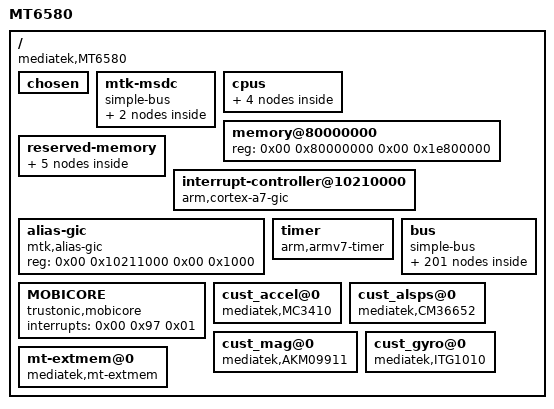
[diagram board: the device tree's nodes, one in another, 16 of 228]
/dts-v1/;

/ {
	model = "MT6580";
	compatible = "mediatek,MT6580";
	interrupt-parent = <0x01>;
	#address-cells = <0x02>;
	#size-cells = <0x02>;

	chosen {
		bootargs = "console=tty0 console=ttyMT0,921600n1 root=/dev/ram initrd=0x84000000,0x400000 loglevel=8";
		atag,videolfb-fb_base = <0x9e800000>;
		atag,videolfb-islcmfound = <0x01>;
		atag,videolfb-fps = <0x1770>;
		atag,videolfb-vramSize = <0x1800000>;
		atag,videolfb-lcmname = "nt35590_AUO";
	};

	mtk-msdc {
		compatible = "simple-bus";
		#address-cells = <0x01>;
		#size-cells = <0x01>;
		ranges = <0x00 0x00 0x00 0xffffffff>;

		MSDC0@0x11120000 {
			compatible = "mediatek,MSDC0";
			reg = <0x11120000 0x10000 0x10001e84 0x02>;
			interrupts = <0x00 0x26 0x08>;
		};

		MSDC1@0x11130000 {
			compatible = "mediatek,MSDC1";
			reg = <0x11130000 0x10000 0x10001e84 0x02>;
			interrupts = <0x00 0x27 0x08>;
		};
	};

	cpus {
		#address-cells = <0x01>;
		#size-cells = <0x00>;

		cpu@0 {
			device_type = "cpu";
			compatible = "arm,cortex-a7";
			reg = <0x00>;
			clock-frequency = <0x6553f100>;
		};

		cpu@1 {
			device_type = "cpu";
			compatible = "arm,cortex-a7";
			reg = <0x01>;
			clock-frequency = <0x6553f100>;
		};

		cpu@2 {
			device_type = "cpu";
			compatible = "arm,cortex-a7";
			reg = <0x02>;
			clock-frequency = <0x6553f100>;
		};

		cpu@3 {
			device_type = "cpu";
			compatible = "arm,cortex-a7";
			reg = <0x03>;
			clock-frequency = <0x6553f100>;
		};
	};

	memory@80000000 {
		device_type = "memory";
		reg = <0x00 0x80000000 0x00 0x1e800000>;
	};

	reserved-memory {
		#address-cells = <0x02>;
		#size-cells = <0x02>;
		ranges;

		reserve-memory-ccci_md1 {
			compatible = "reserve-memory-ccci_md1";
			no-map;
			size = <0x00 0x1800000>;
			alignment = <0x00 0x2000000>;
			alloc-ranges = <0x00 0x80000000 0x00 0x80000000>;
		};

		pstore-reserved-memory {
			compatible = "pstore-reserve-memory";
			reg = <0x00 0x83f10000 0x00 0xe0000>;
		};

		mrdump-reserved-memory {
			compatible = "mrdump-reserved-memory";
			reg = <0x00 0x81f00000 0x00 0x2000>;
		};

		preloader-reserved-memory {
			compatible = "mrdump-reserved-memory";
			reg = <0x00 0x82000000 0x00 0x200000>;
		};

		lk-reserved-memory {
			compatible = "mrdump-reserved-memory";
			reg = <0x00 0x81e00000 0x00 0x100000>;
		};
	};

	interrupt-controller@10210000 {
		compatible = "arm,cortex-a7-gic";
		#interrupt-cells = <0x03>;
		#address-cells = <0x00>;
		interrupt-controller;
		reg = <0x00 0x10211000 0x00 0x1000 0x00 0x10212000 0x00 0x1000 0x00 0x10200100 0x00 0x1000>;
		interrupts = <0x01 0x09 0xf04>;
		linux,phandle = <0x01>;
		phandle = <0x01>;
	};

	alias-gic {
		compatible = "mtk,alias-gic";
		reg = <0x00 0x10211000 0x00 0x1000>;
	};

	timer {
		compatible = "arm,armv7-timer";
		interrupts = <0x01 0x0d 0x08 0x01 0x0e 0x08 0x01 0x0b 0x08 0x01 0x0a 0x08>;
		clock-frequency = <0xc65d40>;
	};

	bus {
		compatible = "simple-bus";
		#address-cells = <0x01>;
		#size-cells = <0x01>;
		ranges = <0x00 0x00 0x00 0xffffffff>;

		TOPCKGEN@0x10000000 {
			compatible = "mediatek,TOPCKGEN";
			reg = <0x10000000 0x1000>;
		};

		INFRACFG_AO@0x10001000 {
			compatible = "mediatek,INFRACFG_AO";
			reg = <0x10001000 0x1000>;
		};

		BAT_METTER {
			compatible = "mediatek,bat_meter";
		};

		BAT_NOTIFY {
			compatible = "mediatek,bat_notify";
		};

		BATTERY {
			compatible = "mediatek,battery";
		};

		KP@0x10002000 {
			compatible = "mediatek,KP";
			reg = <0x10002000 0x1000>;
			interrupts = <0x00 0x6d 0x02>;
		};

		PERICFG@0x10003000 {
			compatible = "mediatek,PERICFG";
			reg = <0x10003000 0x1000>;
		};

		RESERVED@0x10004000 {
			compatible = "mediatek,RESERVED";
			reg = <0x10004000 0x1000>;
		};

		GPIO@0x10005000 {
			compatible = "mediatek,GPIO";
			reg = <0x10005000 0x1000>;
		};

		SLEEP@0x10006000 {
			compatible = "mediatek,SLEEP";
			reg = <0x10006000 0x1000>;
			interrupts = <0x00 0x58 0x08 0x00 0x59 0x08 0x00 0x5a 0x08 0x00 0x5b 0x08>;
		};

		TOPRGU@0x10007000 {
			compatible = "mediatek,TOPRGU";
			reg = <0x10007000 0x1000>;
			interrupts = <0x00 0x9d 0x02>;
		};

		APXGPT@0x10008000 {
			compatible = "mediatek,APXGPT";
			reg = <0x10008000 0x1000>;
			interrupts = <0x00 0x5c 0x08>;
			clock-frequency = <0xc65d40>;
		};

		EFUSEC@0x10009000 {
			compatible = "mediatek,EFUSEC";
			reg = <0x10009000 0x1000>;
		};

		SEJ@0x1000A000 {
			compatible = "mediatek,SEJ";
			reg = <0x1000a000 0x1000>;
			interrupts = <0x00 0x6e 0x00>;
		};

		DBG_DEBUG {
			compatible = "mediatek,DBG_DEBUG";
			num = <0x04>;
			reg = <0x10170000 0x2000 0x10172000 0x2000 0x10174000 0x2000 0x10176000 0x2000>;
		};

		EINTC@0x1000B000 {
			compatible = "mtk,mt-eic";
			reg = <0x1000b000 0x1000>;
			interrupts = <0x00 0x5e 0x04>;
			#interrupt-cells = <0x02>;
			interrupt-controller;
			max_eint_num = <0x1a>;
			mapping_table_entry = <0x53>;
			mapping_table = <0x00 0x00 0x01 0x01 0x02 0x02 0x03 0x03 0x04 0x04 0x05 0x05 0x06 0x06 0x07 0x07 0x08 0x08 0x09 0x09 0x0a 0x0a 0x0b 0x0b 0x0c 0x0c 0x0d 0x0d 0x0e 0x0e 0x0f 0x0f 0x10 0x00 0x11 0x01 0x12 0x02 0x13 0x03 0x14 0x04 0x15 0x05 0x16 0x06 0x17 0x07 0x18 0x08 0x19 0x09 0x1a 0x0a 0x1b 0x0b 0x1c 0x0c 0x1d 0x0d 0x1e 0x0e 0x1f 0x0f 0x20 0x00 0x21 0x01 0x22 0x02 0x23 0x03 0x24 0x04 0x25 0x05 0x26 0x06 0x27 0x07 0x28 0x08 0x29 0x09 0x2a 0x0a 0x2b 0x0b 0x2c 0x0c 0x2d 0x0d 0x2e 0x0e 0x2f 0x0f 0x30 0x00 0x31 0x01 0x32 0x02 0x33 0x03 0x34 0x03 0x35 0x04 0x36 0x05 0x37 0x06 0x38 0x07 0x39 0x08 0x3a 0x0a 0x3b 0x0b 0x3c 0x0c 0x3d 0x0d 0x3e 0x0e 0x3f 0x0f 0x40 0x00 0x41 0x01 0x42 0x02 0x43 0x03 0x44 0x10 0x45 0x04 0x46 0x05 0x47 0x06 0x48 0x07 0x49 0x08 0x4a 0x09 0x4b 0x0a 0x4c 0x0b 0x4d 0x0c 0x4e 0x0d 0x51 0x00 0x52 0x01 0x53 0x02 0x54 0x03>;
			builtin_entry = <0x0b>;
			builtin_mapping = <0x00 0x03 0x14 0x01 0x03 0x12 0x07 0x04 0x14 0x08 0x04 0x12 0x09 0x03 0x14 0x0a 0x03 0x12 0x18 0x05 0x14 0x19 0x05 0x12 0x4d 0x02 0x14 0x4e 0x02 0x12 0x0d 0x01 0x11>;
			linux,phandle = <0x02>;
			phandle = <0x02>;

			ACCDET@0 {
				compatible = "mediatek, ACCDET-eint";
				interrupt-parent = <0x02>;
				interrupts = <0x00 0x08>;
				debounce = <0x00 0x3e800>;
			};

			TOUCH_PANEL@1 {
				compatible = "mediatek, TOUCH_PANEL-eint";
				interrupt-parent = <0x02>;
				interrupts = <0x01 0x02>;
				debounce = <0x01 0x00>;
			};

			MSE@4 {
				compatible = "mediatek, MSE-eint";
				interrupt-parent = <0x02>;
				interrupts = <0x04 0x08>;
				debounce = <0x04 0x00>;
			};

			ALS@5 {
				compatible = "mediatek, ALS-eint";
				interrupt-parent = <0x02>;
				interrupts = <0x05 0x08>;
				debounce = <0x05 0x00>;
			};

			GSE_1@6 {
				compatible = "mediatek, GSE_1-eint";
				interrupt-parent = <0x02>;
				interrupts = <0x06 0x08>;
				debounce = <0x06 0x00>;
			};

			DSI_TE@16 {
				compatible = "mediatek, DSI_TE-eint";
				interrupt-parent = <0x02>;
				interrupts = <0x44 0x01>;
				debounce = <0x44 0x00>;
			};
		};

		AP_CCIF0@0x1000C000 {
			compatible = "mediatek,AP_CCIF0";
			reg = <0x1000c000 0x1000 0x1000d000 0x1000>;
			interrupts = <0x00 0x5d 0x08 0x00 0x98 0x02>;
			ccif0,major = <0xb8>;
			ccif0,minor_base = <0x00>;
			ccif0,capability = <0x02>;
			md_smem_size = <0x200000>;
		};

		MD_CCIF0@0x1000D000 {
			compatible = "mediatek,MD_CCIF0";
			reg = <0x1000d000 0x1000>;
		};

		MCUSYS_CFGREG@0x1020000 {
			compatible = "mediatek,MCUSYS_CFGREG_BASE";
			reg = <0x1020000 0x200>;
		};

		AP_MD_DBGMODE_CFGREG@0x1011A010 {
			compatible = "mediatek,AP_MD_DBGMODE_CFGREG";
			reg = <0x1011a010 0x200>;
		};

		AES@0x1000E000 {
			compatible = "mediatek,AES";
			reg = <0x1000e000 0x1000>;
		};

		PWRAP@0x1000F000 {
			compatible = "mediatek,PWRAP";
			reg = <0x1000f000 0x1000>;
			interrupts = <0x00 0x6c 0x00>;
		};

		DEVAPC_AO@0x10010000 {
			compatible = "mediatek,DEVAPC_AO";
			reg = <0x10010000 0x1000>;
		};

		MIPI_CONFG@0x10011000 {
			compatible = "mediatek,MIPI_CONFG";
			reg = <0x10011000 0x1000>;
		};

		INFRA_MBIST@0x10012000 {
			compatible = "mediatek,INFRA_MBIST";
			reg = <0x10012000 0x1000>;
		};

		RESERVED@0x10013000 {
			compatible = "mediatek,RESERVED";
			reg = <0x10013000 0x1000>;
		};

		IOCFG_T@0x10014000 {
			compatible = "mediatek,IOCFG_T";
			reg = <0x10014000 0x1000>;
		};

		IOCFG_B@0x10015000 {
			compatible = "mediatek,IOCFG_B";
			reg = <0x10015000 0x1000>;
		};

		IOCFG_L@0x10016000 {
			compatible = "mediatek,IOCFG_L";
			reg = <0x10016000 0x1000>;
		};

		IOCFG_R@0x10017000 {
			compatible = "mediatek,IOCFG_R";
			reg = <0x10017000 0x1000>;
		};

		APMIXED@0x10018000 {
			compatible = "mediatek,APMIXED";
			reg = <0x10018000 0x1000>;
		};

		MCUCFG@0x10200000 {
			compatible = "mediatek,MCUCFG";
			reg = <0x10200000 0x1000>;
		};

		INFRACFG@0x10201000 {
			compatible = "mediatek,INFRACFG";
			reg = <0x10201000 0x1000>;
		};

		SYS_CIRQ@0x10202000 {
			compatible = "mediatek,SYS_CIRQ";
			reg = <0x10202000 0x1000>;
			interrupts = <0x00 0x9e 0x08>;
			cirq_num = <0x7e>;
			spi_start_offset = <0x20>;
		};

		M4U@0x10203000 {
			cell-index = <0x00>;
			compatible = "mediatek,M4U";
			reg = <0x10203000 0x1000>;
			interrupts = <0x00 0x51 0x08>;
		};

		DEVAPC@0x10204000 {
			compatible = "mediatek,DEVAPC";
			reg = <0x10204000 0x1000>;
			interrupts = <0x00 0x4a 0x08>;
		};

		EMI@0x10205000 {
			compatible = "mediatek,EMI";
			reg = <0x10205000 0x1000>;
			interrupts = <0x00 0x4c 0x04>;
		};

		DRAMC_NAO@0x10206000 {
			compatible = "mediatek,DRAMC_NAO";
			reg = <0x10206000 0x1000>;
		};

		DRAMC0@0x10207000 {
			compatible = "mediatek,DRAMC0";
			reg = <0x10207000 0x1000>;
		};

		DDRPHY@0x10208000 {
			compatible = "mediatek,DDRPHY";
			reg = <0x10208000 0x1000>;
		};

		SRAMROM@0x10209000 {
			compatible = "mediatek,SRAMROM";
			reg = <0x10209000 0x1000>;
		};

		GCE@0x1020A000 {
			compatible = "mediatek,GCE";
			reg = <0x1020a000 0x1000>;
			interrupts = <0x00 0x55 0x08 0x00 0x56 0x08>;
		};

		BUS_DBG@0x1020B000 {
			compatible = "mediatek,BUS_DBG";
			reg = <0x1020b000 0x1000>;
			interrupts = <0x00 0x49 0x08>;
			two_stage_timeout = <0x01>;
		};

		TRNG@0x1020C000 {
			compatible = "mediatek,TRNG";
			reg = <0x1020c000 0x1000>;
			interrupts = <0x00 0x57 0x08>;
		};

		MCUCFG_BIU@0x1020D000 {
			compatible = "mediatek,MCUCFG_BIU";
			reg = <0x1020d000 0x1000>;
		};

		DBGSYS_DEM@0x1011A000 {
			compatible = "mediatek,DBGSYS_DEM";
			reg = <0x1011a000 0x1000>;
		};

		DBGSYS_CTI@0x10112000 {
			compatible = "mediatek,DBGSYS_CTI";
			reg = <0x10112000 0x1000>;
		};

		DBGSYS_DAPROM@0x10110000 {
			compatible = "mediatek,DBGSYS_DAPROM";
			reg = <0x10110000 0x1000>;
		};

		DBGSYS_CPU@0x10160000 {
			compatible = "mediatek,DBGSYS_CPU";
			reg = <0x10160000 0x20000>;
		};

		DBGSYS_MDSYS@0x10120000 {
			compatible = "mediatek,DBGSYS_MDSYS";
			reg = <0x10120000 0x10000>;
		};

		CQDMA@0x1020AC00 {
			compatible = "mediatek,CQDMA";
			reg = <0x1020ac00 0x1000>;
			interrupts = <0x00 0x4d 0x08>;
			nr_channel = <0x01>;
		};

		AP_DMA@0x11000000 {
			compatible = "mediatek,AP_DMA";
			reg = <0x11000000 0x1000>;
			interrupts = <0x00 0x30 0x08>;
		};

		NFI@0x11001000 {
			compatible = "mediatek,NFI";
			reg = <0x11001000 0x1000>;
			interrupts = <0x00 0x4f 0x08>;
		};

		NFIECC@0x11002000 {
			compatible = "mediatek,NFIECC";
			reg = <0x11002000 0x1000>;
			interrupts = <0x00 0x4e 0x08>;
		};

		AUXADC@0x11003000 {
			compatible = "mediatek,AUXADC";
			reg = <0x11003000 0x1000>;
			interrupts = <0x00 0x23 0x02>;
		};

		FHCTL@0x11004000 {
			compatible = "mediatek,FHCTL";
			reg = <0x11004000 0x1000>;
		};

		AP_UART0@0x11005000 {
			cell-index = <0x00>;
			compatible = "mediatek,AP_UART0";
			reg = <0x11005000 0x1000>;
			interrupts = <0x00 0x2c 0x08>;
		};

		AP_UART1@0x11006000 {
			cell-index = <0x01>;
			compatible = "mediatek,AP_UART1";
			reg = <0x11006000 0x1000>;
			interrupts = <0x00 0x2d 0x08>;
		};

		AP_DMA_UART0_TX@0x11000480 {
			compatible = "mediatek,AP_DMA_UART0_TX";
			reg = <0x11000480 0x80>;
			interrupts = <0x00 0x38 0x08>;
		};

		AP_DMA_UART0_RX@0x11000500 {
			compatible = "mediatek,AP_DMA_UART0_RX";
			reg = <0x11000500 0x80>;
			interrupts = <0x00 0x39 0x08>;
		};

		AP_DMA_UART1_TX@0x11000580 {
			compatible = "mediatek,AP_DMA_UART1_TX";
			reg = <0x11000580 0x80>;
			interrupts = <0x00 0x3a 0x08>;
		};

		AP_DMA_UART1_RX@0x11000600 {
			compatible = "mediatek,AP_DMA_UART1_RX";
			reg = <0x11000600 0x80>;
			interrupts = <0x00 0x3b 0x08>;
		};

		PWM@0x11008000 {
			compatible = "mediatek,PWM";
			reg = <0x11008000 0x1000>;
			interrupts = <0x00 0x24 0x08>;
		};

		I2C0@0x11009000 {
			compatible = "mediatek,I2C0";
			cell-index = <0x00>;
			reg = <0x11009000 0x1000>;
			#address-cells = <0x01>;
			#size-cells = <0x00>;
			interrupts = <0x00 0x28 0x08 0x00 0x32 0x08>;

			CAMERA_MAIN@10 {
				compatible = "mediatek,CAMERA_MAIN";
				reg = <0x10>;
			};

			CAMERA_MAIN_AF@0C {
				compatible = "mediatek,CAMERA_MAIN_AF";
				reg = <0x0c>;
			};

			CAMERA_SUB@36 {
				compatible = "mediatek,CAMERA_SUB";
				reg = <0x36>;
			};
		};

		I2C1@0x1100A000 {
			compatible = "mediatek,I2C1";
			cell-index = <0x01>;
			reg = <0x1100a000 0x1000>;
			#address-cells = <0x01>;
			#size-cells = <0x00>;
			interrupts = <0x00 0x29 0x08 0x00 0x33 0x08>;

			CAP_TOUCH@5D {
				compatible = "mediatek,CAP_TOUCH";
				reg = <0x5d>;
			};

			EXT_BUCK@60 {
				compatible = "mediatek,EXT_BUCK";
				reg = <0x60>;
			};
		};

		I2C2@0x1100B000 {
			compatible = "mediatek,I2C2";
			cell-index = <0x02>;
			reg = <0x1100b000 0x1000>;
			#address-cells = <0x01>;
			#size-cells = <0x00>;
			interrupts = <0x00 0x2a 0x08 0x00 0x34 0x08>;

			STROBE_MAIN@63 {
				compatible = "mediatek,STROBE_MAIN";
				reg = <0x63>;
			};

			MSENSOR@0D {
				compatible = "mediatek,MSENSOR";
				reg = <0x0d>;
			};

			GSENSOR@4C {
				compatible = "mediatek,GSENSOR";
				reg = <0x4c>;
			};

			GYRO@68 {
				compatible = "mediatek,GYRO";
				reg = <0x68>;
			};
		};

		SPI@0x1100C000 {
			compatible = "mediatek,SPI";
			cell-index = <0x00>;
			spi-padmacro = <0x00>;
			reg = <0x1100c000 0x1000>;
			interrupts = <0x00 0x40 0x08>;
		};

		THERM_CTRL@0x1100D000 {
			compatible = "mediatek,THERM_CTRL";
			reg = <0x1100d000 0x1000>;
			interrupts = <0x00 0x25 0x08>;
		};

		AP_DMA_BTIF_TX@0x11000380 {
			compatible = "mediatek,AP_DMA_BTIF_TX";
			reg = <0x11000380 0x80>;
			interrupts = <0x00 0x36 0x08>;
		};

		AP_DMA_BTIF_RX@0x11000400 {
			compatible = "mediatek,AP_DMA_BTIF_RX";
			reg = <0x11000400 0x80>;
			interrupts = <0x00 0x37 0x08>;
		};

		BTIF@0x1100C000 {
			compatible = "mediatek,BTIF";
			reg = <0x1100e000 0x1000>;
			interrupts = <0x00 0x43 0x08>;
		};

		mt3326-gps@0xffffffff {
			compatible = "mediatek,mt3326-gps";
		};

		BTCVSD@0x18000000 {
			compatible = "mediatek,audio_bt_cvsd";
			reg = <0x18000000 0x1000 0x18080000 0x1000>;
			interrupts = <0x00 0x99 0x08>;
		};

		CONSYS@0x18070000 {
			compatible = "mediatek,CONSYS";
			reg = <0x18070000 0x200 0x10007000 0x100 0x10000000 0x2000 0x10006000 0x1000 0x10005000 0x1000>;
			interrupts = <0x00 0x9a 0x08 0x00 0x9c 0x08>;
		};

		WIFI@0x180F0000 {
			compatible = "mediatek,WIFI";
			reg = <0x180f0000 0x5c>;
			interrupts = <0x00 0x9b 0x08>;
		};

		DISP_PWM@0x1100F000 {
			compatible = "mediatek,DISP_PWM";
			reg = <0x1100f000 0x1000>;
			interrupts = <0x00 0x21 0x08>;
		};

		USB0@0x11100000 {
			compatible = "mediatek,USB0";
			cell-index = <0x00>;
			reg = <0x11100000 0x10000 0x11110000 0x10000>;
			interrupts = <0x00 0x20 0x08>;
			mode = <0x02>;
			multipoint = <0x01>;
			dyn_fifo = <0x01>;
			soft_con = <0x01>;
			dma = <0x01>;
			num_eps = <0x10>;
			dma_channels = <0x08>;
			iddig_gpio = <0x09 0x03>;
			drvvbus_gpio = <0x0a 0x03>;
		};

		AUDIO@0x11140000 {
			compatible = "mediatek,AUDIO";
			reg = <0x11140000 0x10000>;
			interrupts = <0x00 0x50 0x08>;
		};

		MT_SOC_DL1_PCM@0x11140000 {
			compatible = "mediatek,mt_soc_pcm_dl1";
			reg = <0x11140000 0x1000>;
			interrupts = <0x00 0x50 0x08>;
			audclk-gpio = <0x1a 0x00>;
			audmiso-gpio = <0x1c 0x00>;
			audmosi-gpio = <0x1b 0x00>;
		};

		MT_SOC_UL1_PCM@0x11140000 {
			compatible = "mediatek,mt_soc_pcm_capture";
		};

		MT_SOC_VOICE_MD1@0x11140000 {
			compatible = "mediatek,mt_soc_pcm_voice_md1";
		};

		MT_SOC_HDMI_PCM@0x11140000 {
			compatible = "mediatek,mt_soc_pcm_hdmi";
		};

		MT_SOC_ULDLLOOPBACK_PCM@0x11140000 {
			compatible = "mediatek,mt_soc_pcm_uldlloopback";
		};

		MT_SOC_I2S0_PCM@0x11140000 {
			compatible = "mediatek,mt_soc_pcm_dl1_i2s0";
		};

		MT_SOC_MRGRX_PCM@0x11140000 {
			compatible = "mediatek,mt_soc_pcm_mrgrx";
		};

		MT_SOC_MRGRX_AWB_PCM@0x11140000 {
			compatible = "mediatek,mt_soc_pcm_mrgrx_awb";
		};

		MT_SOC_FM_I2S_PCM@0x11140000 {
			compatible = "mediatek,mt_soc_pcm_fm_i2s";
		};

		MT_SOC_FM_I2S_AWB_PCM@0x11140000 {
			compatible = "mediatek,mt_soc_pcm_fm_i2s_awb";
		};

		MT_SOC_I2S0DL1_PCM@0x11140000 {
			compatible = "mediatek,mt_soc_pcm_dl1_i2s0Dl1";
		};

		MT_SOC_DL1_AWB_PCM@0x11140000 {
			compatible = "mediatek,mt_soc_pcm_dl1_awb";
		};

		MT_SOC_VOICE_MD1_BT@0x11140000 {
			compatible = "mediatek,mt_soc_pcm_voice_md1_bt";
		};

		MT_SOC_VOIP_BT_OUT@0x11140000 {
			compatible = "mediatek,mt_soc_pcm_dl1_bt";
		};

		MT_SOC_VOIP_BT_IN@0x11140000 {
			compatible = "mediatek,mt_soc_pcm_bt_dai";
		};

		MT_SOC_TDMRX_PCM@0x11140000 {
			compatible = "mediatek,mt_soc_tdm_capture";
		};

		MT_SOC_FM_MRGTX_PCM@0x11140000 {
			compatible = "mediatek,mt_soc_pcm_fmtx";
		};

		MT_SOC_UL2_PCM@0x11140000 {
			compatible = "mediatek,mt_soc_pcm_capture2";
		};

		MT_SOC_I2S0_AWB_PCM@0x11140000 {
			compatible = "mediatek,mt_soc_pcm_i2s0_awb";
		};

		MT_SOC_VOICE_MD2@0x11140000 {
			compatible = "mediatek,mt_soc_pcm_voice_md2";
		};

		MT_SOC_ROUTING_PCM@0x11140000 {
			compatible = "mediatek,mt_soc_pcm_routing";
		};

		MT_SOC_VOICE_MD2_BT@0x11140000 {
			compatible = "mediatek,mt_soc_pcm_voice_md2_bt";
		};

		MT_SOC_HP_IMPEDANCE_PCM@0x11140000 {
			compatible = "mediatek,Mt_soc_pcm_hp_impedance";
		};

		MT_SOC_CODEC_NAME@0x11140000 {
			compatible = "mediatek,mt_soc_codec_63xx";
		};

		MT_SOC_DUMMY_PCM@0x11140000 {
			compatible = "mediatek,mt_soc_pcm_dummy";
		};

		MT_SOC_CODEC_DUMMY_NAME@0x11140000 {
			compatible = "mediatek,mt_soc_codec_dummy";
		};

		MT_SOC_ROUTING_DAI_NAME@0x11140000 {
			compatible = "mediatek,mt_soc_dai_routing";
		};

		MT_SOC_DAI_NAME@0x11140000 {
			compatible = "mediatek,mt_soc_dai_stub";
		};

		AHB_MOM@0x11150000 {
			compatible = "mediatek,AHB_MOM";
			reg = <0x11150000 0x10000>;
		};

		MDI@0x11160000 {
			compatible = "mediatek,MDI";
			reg = <0x11160000 0x10000>;
		};

		G3D_CONFIG@0x13000000 {
			compatible = "mediatek,G3D_CONFIG";
			reg = <0x13000000 0x1000>;
		};

		MALI@0x13010000 {
			compatible = "mediatek,MALI";
			reg = <0x13010000 0x10000>;
		};

		MMSYS_CONFIG@0x14000000 {
			compatible = "mediatek,MMSYS_CONFIG";
			reg = <0x14000000 0x1000>;
			interrupts = <0x00 0x84 0x08>;
		};

		MDP_RDMA@0x14001000 {
			compatible = "mediatek,MDP_RDMA";
			reg = <0x14001000 0x1000>;
			interrupts = <0x00 0x71 0x08>;
		};

		MDP_RSZ0@0x14002000 {
			compatible = "mediatek,MDP_RSZ0";
			reg = <0x14002000 0x1000>;
			interrupts = <0x00 0x72 0x08>;
		};

		MDP_RSZ1@0x14003000 {
			compatible = "mediatek,MDP_RSZ1";
			reg = <0x14003000 0x1000>;
			interrupts = <0x00 0x73 0x08>;
		};

		MDP_WDMA@0x14004000 {
			compatible = "mediatek,MDP_WDMA";
			reg = <0x14004000 0x1000>;
			interrupts = <0x00 0x75 0x08>;
		};

		MDP_WROT@0x14005000 {
			compatible = "mediatek,MDP_WROT";
			reg = <0x14005000 0x1000>;
			interrupts = <0x00 0x76 0x08>;
		};

		MDP_TDSHP@0x14006000 {
			compatible = "mediatek,MDP_TDSHP";
			reg = <0x14006000 0x1000>;
			interrupts = <0x00 0x74 0x08>;
		};

		DISPSYS@0x14007000 {
			compatible = "mediatek,DISPSYS";
			reg = <0x14000000 0x1000 0x14007000 0x1000 0x14008000 0x1000 0x14009000 0x1000 0x1400a000 0x1000 0x1400b000 0x1000 0x1400c000 0x1000 0x1400d000 0x1000 0x1400e000 0x1000 0x1400f000 0x1000 0x14010000 0x1000 0x14011000 0x1000 0x14012000 0x1000 0x14013000 0x1000 0x1100f000 0x1000 0x14015000 0x1000 0x14016000 0x1000 0x14017000 0x1000 0x14018000 0x1000>;
			interrupts = <0x00 0x00 0x08 0x00 0x77 0x08 0x00 0x00 0x08 0x00 0x79 0x08 0x00 0x00 0x08 0x00 0x7b 0x08 0x00 0x7c 0x08 0x00 0x00 0x08 0x00 0x7e 0x08 0x00 0x7f 0x08 0x00 0x80 0x08 0x00 0x00 0x08 0x00 0x82 0x08 0x00 0x00 0x08 0x00 0x00 0x08 0x00 0x70 0x08 0x00 0x00 0x08 0x00 0x00 0x08 0x00 0x00 0x08>;
		};

		DISP_OVL0@0x14007000 {
			compatible = "mediatek,DISP_OVL0";
			reg = <0x14007000 0x1000>;
			interrupts = <0x00 0x77 0x08>;
		};

		DISP_OVL1@0x14008000 {
			compatible = "mediatek,DISP_OVL1";
			reg = <0x14008000 0x1000>;
		};

		DISP_RDMA0@0x14009000 {
			compatible = "mediatek,DISP_RDMA0";
			reg = <0x14009000 0x1000>;
			interrupts = <0x00 0x79 0x08>;
		};

		DISP_RDMA1@0x1400A000 {
			compatible = "mediatek,DISP_RDMA1";
			reg = <0x1400a000 0x1000>;
		};

		DISP_WDMA@0x1400B000 {
			compatible = "mediatek,DISP_WDMA";
			reg = <0x1400b000 0x1000>;
			interrupts = <0x00 0x7b 0x08>;
		};

		DISP_COLOR@0x1400C000 {
			compatible = "mediatek,DISP_COLOR";
			reg = <0x1400c000 0x1000>;
			interrupts = <0x00 0x7c 0x08>;
		};

		DISP_CCORR@0x1400D000 {
			compatible = "mediatek,DISP_CCORR";
			reg = <0x1400d000 0x1000>;
		};

		DISP_AAL@0x1400E000 {
			compatible = "mediatek,DISP_AAL";
			reg = <0x1400e000 0x1000>;
			interrupts = <0x00 0x7e 0x08>;
		};

		DISP_GAMMA@0x1400F000 {
			compatible = "mediatek,DISP_GAMMA";
			reg = <0x1400f000 0x1000>;
			interrupts = <0x00 0x7f 0x08>;
		};

		DISP_DITHER@0x14010000 {
			compatible = "mediatek,DISP_DITHER";
			reg = <0x14010000 0x1000>;
			interrupts = <0x00 0x80 0x08>;
		};

		DISP_UFOE@0x14011000 {
			compatible = "mediatek,DISP_UFOE";
			reg = <0x14011000 0x1000>;
		};

		DSI@0x14012000 {
			compatible = "mediatek,DSI";
			reg = <0x14012000 0x1000>;
		};

		DPI@0x14013000 {
			compatible = "mediatek,DPI";
			reg = <0x14013000 0x1000>;
		};

		PTP_FSM@0x1100D000 {
			compatible = "mediatek,PTP_FSM";
			reg = <0x1100d000 0x1000>;
			interrupts = <0x00 0x2b 0x08>;
		};

		MM_MUTEX@0x14015000 {
			compatible = "mediatek,MM_MUTEX";
			reg = <0x14015000 0x1000>;
			interrupts = <0x00 0x70 0x08>;
		};

		SMI_LARB0@0x14016000 {
			compatible = "mediatek,SMI_LARB0";
			reg = <0x14016000 0x1000>;
			interrupts = <0x00 0x85 0x08>;
		};

		SMI_COMMON@0x14017000 {
			compatible = "mediatek,SMI_COMMON";
			reg = <0x14017000 0x1000 0x14016000 0x1000 0x15001000 0x1000>;
		};

		MIPI_TX_CONFIG@0x14018000 {
			compatible = "mediatek,MIPI_TX_CONFIG";
			reg = <0x14018000 0x1000>;
		};

		ISPSYS@0x15000000 {
			compatible = "mediatek,ISPSYS";
			reg = <0x15004000 0x9000 0x15000000 0x10000 0x10011000 0x4000 0x10017000 0x1000>;
			interrupts = <0x00 0x8e 0x08 0x00 0x8b 0x08>;
		};

		ISP_SYSR@0x15000000 {
			compatible = "mediatek,ISP_SYSR";
		};

		ISP_PIPEM@0x15000000 {
			compatible = "mediatek,ISP_PIPEM";
		};

		KD_CAMERA_HW1@0x15008000 {
			compatible = "mediatek,CAMERA_HW";
			reg = <0x15008000 0x1000>;
		};

		KD_CAMERA_HW2@0x15008000 {
			compatible = "mediatek,CAMERA_HW2";
			reg = <0x15008000 0x1000>;
		};

		SENINF_TOP@0x15008000 {
			compatible = "mediatek,SENINF_TOP";
			reg = <0x15008000 0x1000>;
			interrupts = <0x00 0x8e 0x08>;
		};

		CAM_0@0x15004000 {
			compatible = "mediatek,CAM_0";
			reg = <0x15004000 0x1000>;
			interrupts = <0x00 0x8b 0x08>;
		};

		CAM_1@0x15005000 {
			compatible = "mediatek,CAM_1";
			reg = <0x15005000 0x1000>;
		};

		VENC@0x15009000 {
			compatible = "mediatek,VENC";
			reg = <0x15009000 0x1000>;
			interrupts = <0x00 0x8a 0x08>;
		};

		VDEC@0x1500B000 {
			compatible = "mediatek,VDEC";
			reg = <0x1500b000 0x1000>;
			interrupts = <0x00 0x89 0x08>;
		};

		SMI_LARB1@0x15001000 {
			compatible = "mediatek,SMI_LARB1";
			reg = <0x15001000 0x1000>;
			interrupts = <0x00 0x88 0x08>;
		};

		IMGSYS_CONFIG@0x15000000 {
			compatible = "mediatek,IMGSYS_CONFIG";
			reg = <0x15000000 0x1000>;
		};

		hwmsensor@0 {
			compatible = "mediatek,hwmsensor";
		};

		gsensor@0 {
			compatible = "mediatek,gsensor";
		};

		als_ps@0 {
			compatible = "mediatek,als_ps";
		};

		m_acc_pl@0 {
			compatible = "mediatek,m_acc_pl";
		};

		m_alsps_pl@0 {
			compatible = "mediatek,m_alsps_pl";
		};

		sensorHub@0 {
			compatible = "mediatek,sensorHub";
		};

		shf@0 {
			compatible = "mediatek,shf";
		};

		m_batch_pl@0 {
			compatible = "mediatek,m_batch_pl";
		};

		gyroscope@0 {
			compatible = "mediatek,gyroscope";
		};

		m_gyro_pl@0 {
			compatible = "mediatek,m_gyro_pl";
		};

		barometer@0 {
			compatible = "mediatek,barometer";
		};

		m_baro_pl@0 {
			compatible = "mediatek,m_baro_pl";
		};

		msensor@0 {
			compatible = "mediatek,msensor";
		};

		m_mag_pl@0 {
			compatible = "mediatek,m_mag_pl";
		};

		orientation@0 {
			compatible = "mediatek,orientation";
		};

		pedometer@0 {
			compatible = "mediatek,pedometer";
		};

		m_pdr_pl@0 {
			compatible = "mediatek,m_pdr_pl";
		};

		step_counter@0 {
			compatible = "mediatek,step_counter";
		};

		m_step_c_pl@0 {
			compatible = "mediatek,m_step_c_pl";
		};

		in_pocket@0 {
			compatible = "mediatek,in_pocket";
		};

		m_inpk_pl@0 {
			compatible = "mediatek,m_inpk_pl";
		};

		shake@0 {
			compatible = "mediatek,shake";
		};

		m_shk_pl@0 {
			compatible = "mediatek,m_shk_pl";
		};

		face_down@0 {
			compatible = "mediatek,face_down";
		};

		m_fdn_pl@0 {
			compatible = "mediatek,m_fdn_pl";
		};

		activity@0 {
			compatible = "mediatek,activity";
		};

		m_act_pl@0 {
			compatible = "mediatek,m_act_pl";
		};

		heart_rate@0 {
			compatible = "mediatek,heart_rate";
		};

		m_hrm_pl@0 {
			compatible = "mediatek,m_hrm_pl";
		};

		tilt_detector@0 {
			compatible = "mediatek,tilt_detector";
		};

		m_tilt_pl@0 {
			compatible = "mediatek,m_tilt_pl";
		};

		wake_gesture@0 {
			compatible = "mediatek,wake_gesture";
		};

		m_wag_pl@0 {
			compatible = "mediatek,m_wag_pl";
		};

		glance_gesture@0 {
			compatible = "mediatek,glance_gesture";
		};

		m_glg_pl@0 {
			compatible = "mediatek,m_glg_pl";
		};

		pick_up@0 {
			compatible = "mediatek,pick_up";
		};

		m_pkup_pl@0 {
			compatible = "mediatek,m_pkup_pl";
		};

		MTKFB@0 {
			compatible = "mediatek,MTKFB";
		};
	};

	MOBICORE {
		compatible = "trustonic,mobicore";
		interrupts = <0x00 0x97 0x01>;
	};

	cust_accel@0 {
		compatible = "mediatek,MC3410";
		i2c_num = <0x02>;
		i2c_addr = <0x4c 0x00 0x00 0x00>;
		direction = <0x02>;
		power_id = <0xffff>;
		power_vol = <0x00>;
		firlen = <0x00>;
		is_batch_supported = <0x00>;
	};

	cust_alsps@0 {
		compatible = "mediatek,CM36652";
		i2c_num = <0x02>;
		i2c_addr = <0x60 0x00 0x00 0x00>;
		polling_mode_ps = <0x00>;
		polling_mode_als = <0x01>;
		power_id = <0xffff>;
		power_vol = <0x00>;
		als_level = <0x00 0x7d 0x13f 0x20d 0x443 0x9b0 0xbf2 0x13fb 0x218d 0x2a11 0x3239 0x458f 0x564b 0xffff 0xffff>;
		als_value = <0x00 0x85 0x12f 0x1f8 0x3ea 0x7d3 0xbbe 0x138b 0x1f42 0x2710 0x2ee0 0x3e80 0x4e20 0x4e20 0x4e20 0x4e20>;
		ps_threshold_high = <0x1a>;
		ps_threshold_low = <0x15>;
		is_batch_supported_ps = <0x00>;
		is_batch_supported_als = <0x00>;
	};

	cust_mag@0 {
		compatible = "mediatek,AKM09911";
		i2c_num = <0x02>;
		i2c_addr = <0x0d 0x00 0x00 0x00>;
		direction = <0x04>;
		power_id = <0xffff>;
		power_vol = <0x00>;
		is_batch_supported = <0x00>;
	};

	cust_gyro@0 {
		compatible = "mediatek,ITG1010";
		i2c_num = <0x02>;
		i2c_addr = <0x68 0x00 0x00 0x00>;
		direction = <0x01>;
		power_id = <0xffff>;
		power_vol = <0x00>;
		firlen = <0x00>;
		is_batch_supported = <0x00>;
	};

	mt-extmem@0 {
		compatible = "mediatek,mt-extmem";
	};
};
